# ATSAMC21G17A register map
Vendor: Microchip Technology; Series: SAMC21; File version: 0
CPU: CM0+ r0p0, selectable endian, MPU, no FPU, 2 interrupt priority bits
Registers are 32-bit, read-write, reset 0x0 unless marked. A register's access mark holds for its fields unless they carry their own. Offsets are from the block's base; [hi:lo] are bit positions.

## SDADC — Sigma-Delta Analog Digital Converter
Base 0x42004C00; register names take the prefix SDADC_
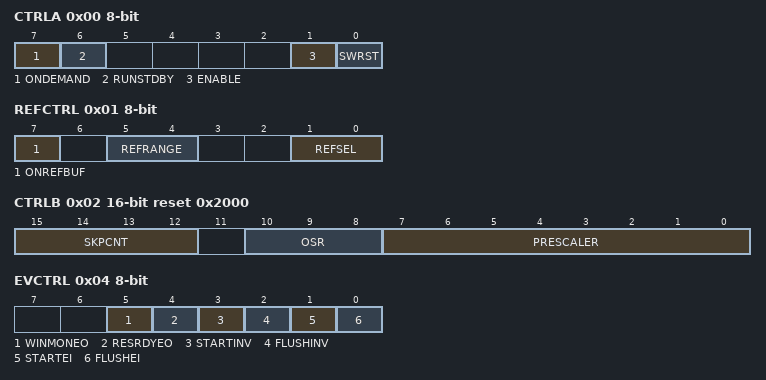
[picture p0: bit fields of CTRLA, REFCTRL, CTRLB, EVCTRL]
0x00 CTRLA 8-bit — Control A
  [7] ONDEMAND — On Demand Control
  [6] RUNSTDBY — Run during Standby
  [1] ENABLE
  [0] SWRST — Software Reset
0x01 REFCTRL 8-bit — Reference Control
  [7] ONREFBUF — Reference Buffer
  [5:4] REFRANGE — Reference Range
  [1:0] REFSEL — Reference Selection
    0=INTREF (Internal Bandgap Reference); 1=AREFB (External Reference); 2=DAC (Internal DAC Output); 3=INTVCC (VDDANA)
0x02 CTRLB 16-bit reset 0x2000 — Control B
  [15:12] SKPCNT — Skip Sample Count
  [10:8] OSR — Over Sampling Ratio
    0=Over Sampling Ratio is 64; 1=Over Sampling Ratio is 128; 2=Over Sampling Ratio is 256; 3=Over Sampling Ratio is 512; 4=Over Sampling Ratio is 1024
  [7:0] PRESCALER — Prescaler Configuration
    0=DIV2 (Peripheral clock divided by 2); 1=DIV4 (Peripheral clock divided by 4); 2=DIV8 (Peripheral clock divided by 8); 3=DIV16 (Peripheral clock divided by 16); 4=DIV32 (Peripheral clock divided by 32); 5=DIV64 (Peripheral clock divided by 64); 6=DIV128 (Peripheral clock divided by 128); 7=DIV256 (Peripheral clock divided by 256)
0x04 EVCTRL 8-bit — Event Control
  [5] WINMONEO — Window Monitor Event Out
  [4] RESRDYEO — Result Ready Event Out
  [3] STARTINV — Satrt Event Invert Enable
  [2] FLUSHINV — Flush Event Invert Enable
  [1] STARTEI — Start Conversion Event Input Enable
  [0] FLUSHEI — Flush Event Input Enable
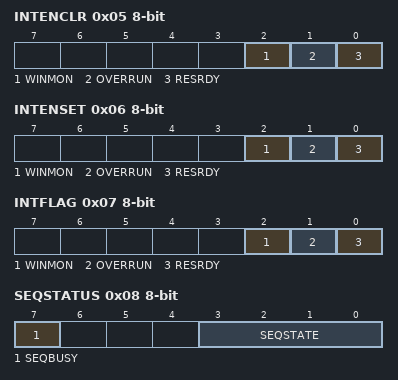
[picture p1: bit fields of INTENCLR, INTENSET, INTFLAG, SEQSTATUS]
0x05 INTENCLR 8-bit — Interrupt Enable Clear
  [2] WINMON — Window Monitor Interrupt Disable
  [1] OVERRUN — Overrun Interrupt Disable
  [0] RESRDY — Result Ready Interrupt Disable
0x06 INTENSET 8-bit — Interrupt Enable Set
  [2] WINMON — Window Monitor Interrupt Enable
  [1] OVERRUN — Overrun Interrupt Enable
  [0] RESRDY — Result Ready Interrupt Enable
0x07 INTFLAG 8-bit — Interrupt Flag Status and Clear
  [2] WINMON write-1-clears — Window Monitor Interrupt Flag
  [1] OVERRUN write-1-clears — Overrun Interrupt Flag
  [0] RESRDY write-1-clears — Result Ready Interrupt Flag
0x08 SEQSTATUS 8-bit ro — Sequence Status
  [7] SEQBUSY — Sequence Busy
  [3:0] SEQSTATE — Sequence State
0x09 INPUTCTRL 8-bit — Input Control
  [3:0] MUXSEL — SDADC Input Selection
    0=AIN0 (SDADC AIN0 Pin); 1=AIN1 (SDADC AIN1 Pin); 2=AIN2 (SDADC AIN2 Pin)
0x0A CTRLC 8-bit — Control C
  [0] FREERUN — Free Running Mode
0x0B WINCTRL 8-bit — Window Monitor Control
  [2:0] WINMODE — Window Monitor Mode
0x0C WINLT — Window Monitor Lower Threshold
  [23:0] WINLT — Window Lower Threshold
0x10 WINUT — Window Monitor Upper Threshold
  [23:0] WINUT — Window Upper Threshold
0x14 OFFSETCORR — Offset Correction
  [23:0] OFFSETCORR — Offset Correction Value
0x18 GAINCORR 16-bit reset 0x1 — Gain Correction
  [13:0] GAINCORR — Gain Correction Value
0x1A SHIFTCORR 8-bit — Shift Correction
  [3:0] SHIFTCORR — Shift Correction Value
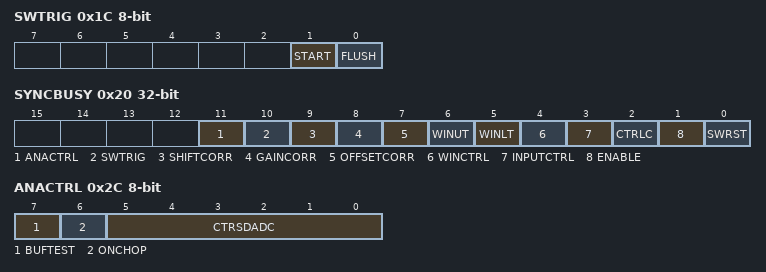
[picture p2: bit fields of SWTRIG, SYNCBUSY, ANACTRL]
0x1C SWTRIG 8-bit — Software Trigger
  [1] START — Start SDADC Conversion
  [0] FLUSH — SDADC Flush
0x20 SYNCBUSY ro — Synchronization Busy
  [11] ANACTRL — ANACTRL Synchronization Busy
  [10] SWTRIG — SWTRG Synchronization Busy
  [9] SHIFTCORR — SHIFTCORR Synchronization Busy
  [8] GAINCORR — GAINCORR Synchronization Busy
  [7] OFFSETCORR — OFFSETCTRL Synchronization Busy
  [6] WINUT — WINUT Synchronization Busy
  [5] WINLT — WINLT Synchronization Busy
  [4] WINCTRL — WINCTRL Synchronization Busy
  [3] INPUTCTRL — INPUTCTRL Synchronization Busy
  [2] CTRLC — CTRLC Synchronization Busy
  [1] ENABLE — ENABLE Synchronization Busy
  [0] SWRST — SWRST Synchronization Busy
0x24 RESULT ro
  [23:0] RESULT — Result Value
0x28 SEQCTRL 8-bit — Sequence Control
  [2:0] SEQEN — Enable Positive Input in the Sequence
0x2C ANACTRL 8-bit — Analog Control
  [7] BUFTEST
  [6] ONCHOP — Chopper
  [5:0] CTRSDADC — SDADC Control
0x2E DBGCTRL 8-bit — Debug Control
  [0] DBGRUN — Debug Run
